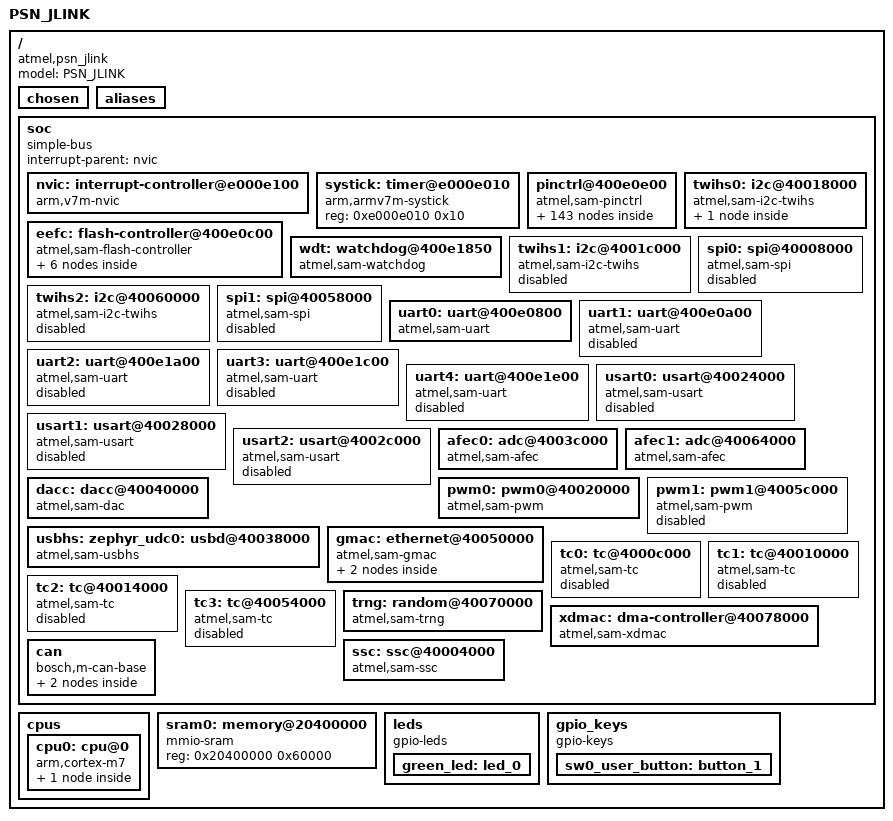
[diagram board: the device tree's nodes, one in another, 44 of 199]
/dts-v1/;

/ {
	#address-cells = < 0x1 >;
	#size-cells = < 0x1 >;
	model = "PSN_JLINK";
	compatible = "atmel,psn_jlink", "atmel,same70q21", "atmel,same70";
	chosen {
		zephyr,flash-controller = &eefc;
		zephyr,entropy = &trng;
		zephyr,console = &uart0;
		zephyr,shell-uart = &uart0;
		zephyr,sram = &sram0;
		zephyr,flash = &flash0;
		zephyr,code-partition = &slot0_partition;
		zephyr,canbus = &can0;
	};
	aliases {
		watchdog0 = &wdt;
		i2c-0 = &twihs0;
		i2c-1 = &twihs1;
		i2c-2 = &twihs2;
		led0 = &green_led;
		sw0 = &sw0_user_button;
	};
	soc {
		#address-cells = < 0x1 >;
		#size-cells = < 0x1 >;
		compatible = "simple-bus";
		interrupt-parent = < &nvic >;
		ranges;
		nvic: interrupt-controller@e000e100 {
			#address-cells = < 0x1 >;
			compatible = "arm,v7m-nvic";
			reg = < 0xe000e100 0xc00 >;
			interrupt-controller;
			#interrupt-cells = < 0x2 >;
			arm,num-irq-priority-bits = < 0x3 >;
			phandle = < 0x1 >;
		};
		systick: timer@e000e010 {
			compatible = "arm,armv7m-systick";
			reg = < 0xe000e010 0x10 >;
		};
		pinctrl@400e0e00 {
			compatible = "atmel,sam-pinctrl";
			#address-cells = < 0x1 >;
			#size-cells = < 0x1 >;
			ranges = < 0x400e0e00 0x400e0e00 0xa00 >;
			pa8b_afec0_adtrg: pa8b_afec0_adtrg {
				atmel,pins = < &pioa 0x8 0x1 >;
				phandle = < 0x19 >;
			};
			pd9c_afec1_adtrg: pd9c_afec1_adtrg {
				atmel,pins = < &piod 0x9 0x2 >;
				phandle = < 0x1a >;
			};
			pd13a_gmac_gcol: pd13a_gmac_gcol {
				atmel,pins = < &piod 0xd 0x0 >;
			};
			pd10a_gmac_gcrs: pd10a_gmac_gcrs {
				atmel,pins = < &piod 0xa 0x0 >;
			};
			pd8a_gmac_gmdc: pd8a_gmac_gmdc {
				atmel,pins = < &piod 0x8 0x0 >;
				phandle = < 0x23 >;
			};
			pd9a_gmac_gmdio: pd9a_gmac_gmdio {
				atmel,pins = < &piod 0x9 0x0 >;
				phandle = < 0x24 >;
			};
			pd14a_gmac_grxck: pd14a_gmac_grxck {
				atmel,pins = < &piod 0xe 0x0 >;
			};
			pd4a_gmac_grxdv: pd4a_gmac_grxdv {
				atmel,pins = < &piod 0x4 0x0 >;
				phandle = < 0x1f >;
			};
			pd7a_gmac_grxer: pd7a_gmac_grxer {
				atmel,pins = < &piod 0x7 0x0 >;
				phandle = < 0x22 >;
			};
			pd5a_gmac_grx0: pd5a_gmac_grx0 {
				atmel,pins = < &piod 0x5 0x0 >;
				phandle = < 0x20 >;
			};
			pd6a_gmac_grx1: pd6a_gmac_grx1 {
				atmel,pins = < &piod 0x6 0x0 >;
				phandle = < 0x21 >;
			};
			pd11a_gmac_grx2: pd11a_gmac_grx2 {
				atmel,pins = < &piod 0xb 0x0 >;
			};
			pd12a_gmac_grx3: pd12a_gmac_grx3 {
				atmel,pins = < &piod 0xc 0x0 >;
			};
			pb1b_gmac_gtsucomp: pb1b_gmac_gtsucomp {
				atmel,pins = < &piob 0x1 0x1 >;
			};
			pb12b_gmac_gtsucomp: pb12b_gmac_gtsucomp {
				atmel,pins = < &piob 0xc 0x1 >;
			};
			pd11c_gmac_gtsucomp: pd11c_gmac_gtsucomp {
				atmel,pins = < &piod 0xb 0x2 >;
			};
			pd20c_gmac_gtsucomp: pd20c_gmac_gtsucomp {
				atmel,pins = < &piod 0x14 0x2 >;
			};
			pd0a_gmac_gtxck: pd0a_gmac_gtxck {
				atmel,pins = < &piod 0x0 0x0 >;
				phandle = < 0x1b >;
			};
			pd1a_gmac_gtxen: pd1a_gmac_gtxen {
				atmel,pins = < &piod 0x1 0x0 >;
				phandle = < 0x1c >;
			};
			pd17a_gmac_gtxer: pd17a_gmac_gtxer {
				atmel,pins = < &piod 0x11 0x0 >;
			};
			pd2a_gmac_gtx0: pd2a_gmac_gtx0 {
				atmel,pins = < &piod 0x2 0x0 >;
				phandle = < 0x1d >;
			};
			pd3a_gmac_gtx1: pd3a_gmac_gtx1 {
				atmel,pins = < &piod 0x3 0x0 >;
				phandle = < 0x1e >;
			};
			pd15a_gmac_gtx2: pd15a_gmac_gtx2 {
				atmel,pins = < &piod 0xf 0x0 >;
			};
			pd16a_gmac_gtx3: pd16a_gmac_gtx3 {
				atmel,pins = < &piod 0x10 0x0 >;
			};
			pd20b_spi0_miso: pd20b_spi0_miso {
				atmel,pins = < &piod 0x14 0x1 >;
			};
			pd21b_spi0_mosi: pd21b_spi0_mosi {
				atmel,pins = < &piod 0x15 0x1 >;
			};
			pb2d_spi0_npcs0: pb2d_spi0_npcs0 {
				atmel,pins = < &piob 0x2 0x3 >;
			};
			pa31a_spi0_npcs1: pa31a_spi0_npcs1 {
				atmel,pins = < &pioa 0x1f 0x0 >;
			};
			pd25b_spi0_npcs1: pd25b_spi0_npcs1 {
				atmel,pins = < &piod 0x19 0x1 >;
			};
			pd12c_spi0_npcs2: pd12c_spi0_npcs2 {
				atmel,pins = < &piod 0xc 0x2 >;
			};
			pd27b_spi0_npcs3: pd27b_spi0_npcs3 {
				atmel,pins = < &piod 0x1b 0x1 >;
				phandle = < 0x10 >;
			};
			pd22b_spi0_spck: pd22b_spi0_spck {
				atmel,pins = < &piod 0x16 0x1 >;
			};
			pc26c_spi1_miso: pc26c_spi1_miso {
				atmel,pins = < &pioc 0x1a 0x2 >;
				phandle = < 0xd >;
			};
			pc27c_spi1_mosi: pc27c_spi1_mosi {
				atmel,pins = < &pioc 0x1b 0x2 >;
				phandle = < 0xe >;
			};
			pc25c_spi1_npcs0: pc25c_spi1_npcs0 {
				atmel,pins = < &pioc 0x19 0x2 >;
			};
			pc28c_spi1_npcs1: pc28c_spi1_npcs1 {
				atmel,pins = < &pioc 0x1c 0x2 >;
			};
			pd0c_spi1_npcs1: pd0c_spi1_npcs1 {
				atmel,pins = < &piod 0x0 0x2 >;
			};
			pc29c_spi1_npcs2: pc29c_spi1_npcs2 {
				atmel,pins = < &pioc 0x1d 0x2 >;
			};
			pd1c_spi1_npcs2: pd1c_spi1_npcs2 {
				atmel,pins = < &piod 0x1 0x2 >;
			};
			pc30c_spi1_npcs3: pc30c_spi1_npcs3 {
				atmel,pins = < &pioc 0x1e 0x2 >;
			};
			pd2c_spi1_npcs3: pd2c_spi1_npcs3 {
				atmel,pins = < &piod 0x2 0x2 >;
			};
			pc24c_spi1_spck: pc24c_spi1_spck {
				atmel,pins = < &pioc 0x18 0x2 >;
				phandle = < 0xf >;
			};
			pa10c_ssc_rd: pa10c_ssc_rd {
				atmel,pins = < &pioa 0xa 0x2 >;
				phandle = < 0x29 >;
			};
			pd24b_ssc_rf: pd24b_ssc_rf {
				atmel,pins = < &piod 0x18 0x1 >;
				phandle = < 0x27 >;
			};
			pa22a_ssc_rk: pa22a_ssc_rk {
				atmel,pins = < &pioa 0x16 0x0 >;
				phandle = < 0x28 >;
			};
			pb5d_ssc_td: pb5d_ssc_td {
				atmel,pins = < &piob 0x5 0x3 >;
				phandle = < 0x2c >;
			};
			pd10c_ssc_td: pd10c_ssc_td {
				atmel,pins = < &piod 0xa 0x2 >;
			};
			pd26b_ssc_td: pd26b_ssc_td {
				atmel,pins = < &piod 0x1a 0x1 >;
			};
			pb0d_ssc_tf: pb0d_ssc_tf {
				atmel,pins = < &piob 0x0 0x3 >;
				phandle = < 0x2a >;
			};
			pb1d_ssc_tk: pb1d_ssc_tk {
				atmel,pins = < &piob 0x1 0x3 >;
				phandle = < 0x2b >;
			};
			pa4a_twihs0_twck0: pa4a_twihs0_twck0 {
				atmel,pins = < &pioa 0x4 0x0 >;
				phandle = < 0x7 >;
			};
			pa3a_twihs0_twd0: pa3a_twihs0_twd0 {
				atmel,pins = < &pioa 0x3 0x0 >;
				phandle = < 0x8 >;
			};
			pb5a_twihs1_twck1: pb5a_twihs1_twck1 {
				atmel,pins = < &piob 0x5 0x0 >;
				phandle = < 0x9 >;
			};
			pb4a_twihs1_twd1: pb4a_twihs1_twd1 {
				atmel,pins = < &piob 0x4 0x0 >;
				phandle = < 0xa >;
			};
			pd28c_twihs2_twck2: pd28c_twihs2_twck2 {
				atmel,pins = < &piod 0x1c 0x2 >;
				phandle = < 0xb >;
			};
			pd27c_twihs2_twd2: pd27c_twihs2_twd2 {
				atmel,pins = < &piod 0x1b 0x2 >;
				phandle = < 0xc >;
			};
			pa9a_uart0_urxd0: pa9a_uart0_urxd0 {
				atmel,pins = < &pioa 0x9 0x0 >;
				phandle = < 0x11 >;
			};
			pa10a_uart0_utxd0: pa10a_uart0_utxd0 {
				atmel,pins = < &pioa 0xa 0x0 >;
				phandle = < 0x12 >;
			};
			pa5c_uart1_urxd1: pa5c_uart1_urxd1 {
				atmel,pins = < &pioa 0x5 0x2 >;
			};
			pa4c_uart1_utxd1: pa4c_uart1_utxd1 {
				atmel,pins = < &pioa 0x4 0x2 >;
			};
			pa6c_uart1_utxd1: pa6c_uart1_utxd1 {
				atmel,pins = < &pioa 0x6 0x2 >;
			};
			pd26d_uart1_utxd1: pd26d_uart1_utxd1 {
				atmel,pins = < &piod 0x1a 0x3 >;
			};
			pd25c_uart2_urxd2: pd25c_uart2_urxd2 {
				atmel,pins = < &piod 0x19 0x2 >;
			};
			pd26c_uart2_utxd2: pd26c_uart2_utxd2 {
				atmel,pins = < &piod 0x1a 0x2 >;
			};
			pd28a_uart3_urxd3: pd28a_uart3_urxd3 {
				atmel,pins = < &piod 0x1c 0x0 >;
			};
			pd30a_uart3_utxd3: pd30a_uart3_utxd3 {
				atmel,pins = < &piod 0x1e 0x0 >;
			};
			pd31b_uart3_utxd3: pd31b_uart3_utxd3 {
				atmel,pins = < &piod 0x1f 0x1 >;
			};
			pd18c_uart4_urxd4: pd18c_uart4_urxd4 {
				atmel,pins = < &piod 0x12 0x2 >;
			};
			pd3c_uart4_utxd4: pd3c_uart4_utxd4 {
				atmel,pins = < &piod 0x3 0x2 >;
			};
			pd19c_uart4_utxd4: pd19c_uart4_utxd4 {
				atmel,pins = < &piod 0x13 0x2 >;
			};
			pb2c_usart0_cts0: pb2c_usart0_cts0 {
				atmel,pins = < &piob 0x2 0x2 >;
			};
			pd0d_usart0_dcd0: pd0d_usart0_dcd0 {
				atmel,pins = < &piod 0x0 0x3 >;
			};
			pd2d_usart0_dsr0: pd2d_usart0_dsr0 {
				atmel,pins = < &piod 0x2 0x3 >;
			};
			pd1d_usart0_dtr0: pd1d_usart0_dtr0 {
				atmel,pins = < &piod 0x1 0x3 >;
			};
			pd3d_usart0_ri0: pd3d_usart0_ri0 {
				atmel,pins = < &piod 0x3 0x3 >;
			};
			pb3c_usart0_rts0: pb3c_usart0_rts0 {
				atmel,pins = < &piob 0x3 0x2 >;
			};
			pb0c_usart0_rxd0: pb0c_usart0_rxd0 {
				atmel,pins = < &piob 0x0 0x2 >;
				phandle = < 0x13 >;
			};
			pb13c_usart0_sck0: pb13c_usart0_sck0 {
				atmel,pins = < &piob 0xd 0x2 >;
			};
			pb1c_usart0_txd0: pb1c_usart0_txd0 {
				atmel,pins = < &piob 0x1 0x2 >;
				phandle = < 0x14 >;
			};
			pa25a_usart1_cts1: pa25a_usart1_cts1 {
				atmel,pins = < &pioa 0x19 0x0 >;
			};
			pa26a_usart1_dcd1: pa26a_usart1_dcd1 {
				atmel,pins = < &pioa 0x1a 0x0 >;
			};
			pa28a_usart1_dsr1: pa28a_usart1_dsr1 {
				atmel,pins = < &pioa 0x1c 0x0 >;
			};
			pa27a_usart1_dtr1: pa27a_usart1_dtr1 {
				atmel,pins = < &pioa 0x1b 0x0 >;
			};
			pa3b_usart1_loncol1: pa3b_usart1_loncol1 {
				atmel,pins = < &pioa 0x3 0x1 >;
			};
			pa29a_usart1_ri1: pa29a_usart1_ri1 {
				atmel,pins = < &pioa 0x1d 0x0 >;
			};
			pa24a_usart1_rts1: pa24a_usart1_rts1 {
				atmel,pins = < &pioa 0x18 0x0 >;
			};
			pa21a_usart1_rxd1: pa21a_usart1_rxd1 {
				atmel,pins = < &pioa 0x15 0x0 >;
				phandle = < 0x15 >;
			};
			pa23a_usart1_sck1: pa23a_usart1_sck1 {
				atmel,pins = < &pioa 0x17 0x0 >;
			};
			pb4d_usart1_txd1: pb4d_usart1_txd1 {
				atmel,pins = < &piob 0x4 0x3 >;
				phandle = < 0x16 >;
			};
			pd19b_usart2_cts2: pd19b_usart2_cts2 {
				atmel,pins = < &piod 0x13 0x1 >;
			};
			pd4d_usart2_dcd2: pd4d_usart2_dcd2 {
				atmel,pins = < &piod 0x4 0x3 >;
			};
			pd6d_usart2_dsr2: pd6d_usart2_dsr2 {
				atmel,pins = < &piod 0x6 0x3 >;
			};
			pd5d_usart2_dtr2: pd5d_usart2_dtr2 {
				atmel,pins = < &piod 0x5 0x3 >;
			};
			pd7d_usart2_ri2: pd7d_usart2_ri2 {
				atmel,pins = < &piod 0x7 0x3 >;
			};
			pd18b_usart2_rts2: pd18b_usart2_rts2 {
				atmel,pins = < &piod 0x12 0x1 >;
			};
			pd15b_usart2_rxd2: pd15b_usart2_rxd2 {
				atmel,pins = < &piod 0xf 0x1 >;
				phandle = < 0x17 >;
			};
			pd17b_usart2_sck2: pd17b_usart2_sck2 {
				atmel,pins = < &piod 0x11 0x1 >;
			};
			pd16b_usart2_txd2: pd16b_usart2_txd2 {
				atmel,pins = < &piod 0x10 0x1 >;
				phandle = < 0x18 >;
			};
			pa4b_tc0_tclk0: pa4b_tc0_tclk0 {
				atmel,pins = < &pioa 0x4 0x1 >;
			};
			pa28b_tc0_tclk1: pa28b_tc0_tclk1 {
				atmel,pins = < &pioa 0x1c 0x1 >;
			};
			pa29b_tc0_tclk2: pa29b_tc0_tclk2 {
				atmel,pins = < &pioa 0x1d 0x1 >;
			};
			pa0b_tc0_tioa0: pa0b_tc0_tioa0 {
				atmel,pins = < &pioa 0x0 0x1 >;
			};
			pa15b_tc0_tioa1: pa15b_tc0_tioa1 {
				atmel,pins = < &pioa 0xf 0x1 >;
			};
			pa26b_tc0_tioa2: pa26b_tc0_tioa2 {
				atmel,pins = < &pioa 0x1a 0x1 >;
			};
			pa1b_tc0_tiob0: pa1b_tc0_tiob0 {
				atmel,pins = < &pioa 0x1 0x1 >;
			};
			pa16b_tc0_tiob1: pa16b_tc0_tiob1 {
				atmel,pins = < &pioa 0x10 0x1 >;
			};
			pa27b_tc0_tiob2: pa27b_tc0_tiob2 {
				atmel,pins = < &pioa 0x1b 0x1 >;
			};
			pc25b_tc1_tclk3: pc25b_tc1_tclk3 {
				atmel,pins = < &pioc 0x19 0x1 >;
			};
			pc28b_tc1_tclk4: pc28b_tc1_tclk4 {
				atmel,pins = < &pioc 0x1c 0x1 >;
			};
			pc31b_tc1_tclk5: pc31b_tc1_tclk5 {
				atmel,pins = < &pioc 0x1f 0x1 >;
			};
			pc23b_tc1_tioa3: pc23b_tc1_tioa3 {
				atmel,pins = < &pioc 0x17 0x1 >;
			};
			pc26b_tc1_tioa4: pc26b_tc1_tioa4 {
				atmel,pins = < &pioc 0x1a 0x1 >;
			};
			pc29b_tc1_tioa5: pc29b_tc1_tioa5 {
				atmel,pins = < &pioc 0x1d 0x1 >;
			};
			pc24b_tc1_tiob3: pc24b_tc1_tiob3 {
				atmel,pins = < &pioc 0x18 0x1 >;
			};
			pc27b_tc1_tiob4: pc27b_tc1_tiob4 {
				atmel,pins = < &pioc 0x1b 0x1 >;
			};
			pc30b_tc1_tiob5: pc30b_tc1_tiob5 {
				atmel,pins = < &pioc 0x1e 0x1 >;
			};
			pc7b_tc2_tclk6: pc7b_tc2_tclk6 {
				atmel,pins = < &pioc 0x7 0x1 >;
			};
			pc10b_tc2_tclk7: pc10b_tc2_tclk7 {
				atmel,pins = < &pioc 0xa 0x1 >;
			};
			pc14b_tc2_tclk8: pc14b_tc2_tclk8 {
				atmel,pins = < &pioc 0xe 0x1 >;
			};
			pc5b_tc2_tioa6: pc5b_tc2_tioa6 {
				atmel,pins = < &pioc 0x5 0x1 >;
			};
			pc8b_tc2_tioa7: pc8b_tc2_tioa7 {
				atmel,pins = < &pioc 0x8 0x1 >;
			};
			pc11b_tc2_tioa8: pc11b_tc2_tioa8 {
				atmel,pins = < &pioc 0xb 0x1 >;
			};
			pc6b_tc2_tiob6: pc6b_tc2_tiob6 {
				atmel,pins = < &pioc 0x6 0x1 >;
			};
			pc9b_tc2_tiob7: pc9b_tc2_tiob7 {
				atmel,pins = < &pioc 0x9 0x1 >;
			};
			pc12b_tc2_tiob8: pc12b_tc2_tiob8 {
				atmel,pins = < &pioc 0xc 0x1 >;
			};
			pe2b_tc3_tclk9: pe2b_tc3_tclk9 {
				atmel,pins = < &pioe 0x2 0x1 >;
			};
			pe5b_tc3_tclk10: pe5b_tc3_tclk10 {
				atmel,pins = < &pioe 0x5 0x1 >;
			};
			pd24c_tc3_tclk11: pd24c_tc3_tclk11 {
				atmel,pins = < &piod 0x18 0x2 >;
			};
			pe0b_tc3_tioa9: pe0b_tc3_tioa9 {
				atmel,pins = < &pioe 0x0 0x1 >;
			};
			pe3b_tc3_tioa10: pe3b_tc3_tioa10 {
				atmel,pins = < &pioe 0x3 0x1 >;
			};
			pd21c_tc3_tioa11: pd21c_tc3_tioa11 {
				atmel,pins = < &piod 0x15 0x2 >;
			};
			pe1b_tc3_tiob9: pe1b_tc3_tiob9 {
				atmel,pins = < &pioe 0x1 0x1 >;
			};
			pe4b_tc3_tiob10: pe4b_tc3_tiob10 {
				atmel,pins = < &pioe 0x4 0x1 >;
			};
			pd22c_tc3_tiob11: pd22c_tc3_tiob11 {
				atmel,pins = < &piod 0x16 0x2 >;
			};
			pb3a_can0_rx0: pb3a_can0_rx0 {
				atmel,pins = < &piob 0x3 0x0 >;
				phandle = < 0x2d >;
			};
			pb2a_can0_tx0: pb2a_can0_tx0 {
				atmel,pins = < &piob 0x2 0x0 >;
				phandle = < 0x2e >;
			};
			pc12c_can1_rx1: pc12c_can1_rx1 {
				atmel,pins = < &pioc 0xc 0x2 >;
			};
			pc14c_can1_tx1: pc14c_can1_tx1 {
				atmel,pins = < &pioc 0xe 0x2 >;
			};
			pioa: gpio@400e0e00 {
				compatible = "atmel,sam-gpio";
				reg = < 0x400e0e00 0x190 >;
				interrupts = < 0xa 0x1 >;
				peripheral-id = < 0xa >;
				label = "PORTA";
				gpio-controller;
				#gpio-cells = < 0x2 >;
				#atmel,pin-cells = < 0x2 >;
				phandle = < 0x2 >;
			};
			piob: gpio@400e1000 {
				compatible = "atmel,sam-gpio";
				reg = < 0x400e1000 0x190 >;
				interrupts = < 0xb 0x1 >;
				peripheral-id = < 0xb >;
				label = "PORTB";
				gpio-controller;
				#gpio-cells = < 0x2 >;
				#atmel,pin-cells = < 0x2 >;
				phandle = < 0x4 >;
			};
			pioc: gpio@400e1200 {
				compatible = "atmel,sam-gpio";
				reg = < 0x400e1200 0x190 >;
				interrupts = < 0xc 0x1 >;
				peripheral-id = < 0xc >;
				label = "PORTC";
				gpio-controller;
				#gpio-cells = < 0x2 >;
				#atmel,pin-cells = < 0x2 >;
				phandle = < 0x5 >;
			};
			piod: gpio@400e1400 {
				compatible = "atmel,sam-gpio";
				reg = < 0x400e1400 0x190 >;
				interrupts = < 0x10 0x1 >;
				peripheral-id = < 0x10 >;
				label = "PORTD";
				gpio-controller;
				#gpio-cells = < 0x2 >;
				#atmel,pin-cells = < 0x2 >;
				phandle = < 0x3 >;
			};
			pioe: gpio@400e1600 {
				compatible = "atmel,sam-gpio";
				reg = < 0x400e1600 0x190 >;
				interrupts = < 0x11 0x1 >;
				peripheral-id = < 0x11 >;
				label = "PORTE";
				gpio-controller;
				#gpio-cells = < 0x2 >;
				#atmel,pin-cells = < 0x2 >;
				phandle = < 0x6 >;
			};
		};
		eefc: flash-controller@400e0c00 {
			compatible = "atmel,sam-flash-controller";
			label = "FLASH_CTRL";
			reg = < 0x400e0c00 0x200 >;
			interrupts = < 0x6 0x0 >;
			peripheral-id = < 0x6 >;
			#address-cells = < 0x1 >;
			#size-cells = < 0x1 >;
			flash0: flash@400000 {
				compatible = "soc-nv-flash";
				label = "FLASH_E70";
				write-block-size = < 0x10 >;
				erase-block-size = < 0x2000 >;
				reg = < 0x400000 0x200000 >;
				partitions {
					compatible = "fixed-partitions";
					#address-cells = < 0x1 >;
					#size-cells = < 0x1 >;
					boot_partition: partition@0 {
						label = "mcuboot";
						reg = < 0x0 0x10000 >;
						read-only;
					};
					slot0_partition: partition@20000 {
						label = "image-0";
						reg = < 0x20000 0xe0000 >;
					};
					slot1_partition: partition@100000 {
						label = "image-1";
						reg = < 0x100000 0xe0000 >;
					};
					scratch_partition: partition@1e0000 {
						label = "image-scratch";
						reg = < 0x1e0000 0x20000 >;
					};
				};
			};
		};
		wdt: watchdog@400e1850 {
			compatible = "atmel,sam-watchdog";
			reg = < 0x400e1850 0xc >;
			interrupts = < 0x4 0x0 >;
			peripheral-id = < 0x4 >;
			label = "WATCHDOG_0";
			status = "okay";
		};
		twihs0: i2c@40018000 {
			compatible = "atmel,sam-i2c-twihs";
			clock-frequency = < 0x186a0 >;
			#address-cells = < 0x1 >;
			#size-cells = < 0x0 >;
			reg = < 0x40018000 0x12b >;
			interrupts = < 0x13 0x0 >;
			peripheral-id = < 0x13 >;
			label = "I2C_0";
			status = "okay";
			pinctrl-0 = < &pa4a_twihs0_twck0 &pa3a_twihs0_twd0 >;
			ag416@38 {
				compatible = "fujikaru,ag416";
				reg = < 0x38 >;
				label = "AG416";
			};
		};
		twihs1: i2c@4001c000 {
			compatible = "atmel,sam-i2c-twihs";
			clock-frequency = < 0x186a0 >;
			#address-cells = < 0x1 >;
			#size-cells = < 0x0 >;
			reg = < 0x4001c000 0x12b >;
			interrupts = < 0x14 0x0 >;
			peripheral-id = < 0x14 >;
			label = "I2C_1";
			status = "disabled";
			pinctrl-0 = < &pb5a_twihs1_twck1 &pb4a_twihs1_twd1 >;
		};
		twihs2: i2c@40060000 {
			compatible = "atmel,sam-i2c-twihs";
			clock-frequency = < 0x186a0 >;
			#address-cells = < 0x1 >;
			#size-cells = < 0x0 >;
			reg = < 0x40060000 0x12b >;
			interrupts = < 0x29 0x0 >;
			peripheral-id = < 0x29 >;
			label = "I2C_2";
			status = "disabled";
			pinctrl-0 = < &pd28c_twihs2_twck2 &pd27c_twihs2_twd2 >;
		};
		spi0: spi@40008000 {
			compatible = "atmel,sam-spi";
			#address-cells = < 0x1 >;
			#size-cells = < 0x0 >;
			reg = < 0x40008000 0x4000 >;
			interrupts = < 0x15 0x0 >;
			peripheral-id = < 0x15 >;
			label = "SPI_0";
			status = "disabled";
			pinctrl-0 = < &pc26c_spi1_miso &pc27c_spi1_mosi &pc24c_spi1_spck &pd27b_spi0_npcs3 >;
		};
		spi1: spi@40058000 {
			compatible = "atmel,sam-spi";
			#address-cells = < 0x1 >;
			#size-cells = < 0x0 >;
			reg = < 0x40058000 0x4000 >;
			interrupts = < 0x2a 0x0 >;
			peripheral-id = < 0x2a >;
			label = "SPI_1";
			status = "disabled";
			pinctrl-0 = < &pc26c_spi1_miso &pc27c_spi1_mosi &pc24c_spi1_spck >;
		};
		uart0: uart@400e0800 {
			compatible = "atmel,sam-uart";
			reg = < 0x400e0800 0x100 >;
			interrupts = < 0x7 0x1 >;
			peripheral-id = < 0x7 >;
			status = "okay";
			label = "UART_0";
			pinctrl-0 = < &pa9a_uart0_urxd0 &pa10a_uart0_utxd0 >;
			current-speed = < 0x1c200 >;
		};
		uart1: uart@400e0a00 {
			compatible = "atmel,sam-uart";
			reg = < 0x400e0a00 0x100 >;
			interrupts = < 0x8 0x1 >;
			peripheral-id = < 0x8 >;
			status = "disabled";
			label = "UART_1";
		};
		uart2: uart@400e1a00 {
			compatible = "atmel,sam-uart";
			reg = < 0x400e1a00 0x100 >;
			interrupts = < 0x2c 0x1 >;
			peripheral-id = < 0x2c >;
			status = "disabled";
			label = "UART_2";
		};
		uart3: uart@400e1c00 {
			compatible = "atmel,sam-uart";
			reg = < 0x400e1c00 0x100 >;
			interrupts = < 0x2d 0x1 >;
			peripheral-id = < 0x2d >;
			status = "disabled";
			label = "UART_3";
		};
		uart4: uart@400e1e00 {
			compatible = "atmel,sam-uart";
			reg = < 0x400e1e00 0x100 >;
			interrupts = < 0x2e 0x1 >;
			peripheral-id = < 0x2e >;
			status = "disabled";
			label = "UART_4";
		};
		usart0: usart@40024000 {
			compatible = "atmel,sam-usart";
			reg = < 0x40024000 0x100 >;
			interrupts = < 0xd 0x0 >;
			peripheral-id = < 0xd >;
			status = "disabled";
			label = "USART_0";
			pinctrl-0 = < &pb0c_usart0_rxd0 &pb1c_usart0_txd0 >;
		};
		usart1: usart@40028000 {
			compatible = "atmel,sam-usart";
			reg = < 0x40028000 0x100 >;
			interrupts = < 0xe 0x0 >;
			peripheral-id = < 0xe >;
			status = "disabled";
			label = "USART_1";
			pinctrl-0 = < &pa21a_usart1_rxd1 &pb4d_usart1_txd1 >;
		};
		usart2: usart@4002c000 {
			compatible = "atmel,sam-usart";
			reg = < 0x4002c000 0x100 >;
			interrupts = < 0xf 0x0 >;
			peripheral-id = < 0xf >;
			status = "disabled";
			label = "USART_2";
			pinctrl-0 = < &pd15b_usart2_rxd2 &pd16b_usart2_txd2 >;
		};
		afec0: adc@4003c000 {
			compatible = "atmel,sam-afec";
			reg = < 0x4003c000 0x100 >;
			interrupts = < 0x1d 0x0 >;
			peripheral-id = < 0x1d >;
			status = "okay";
			label = "ADC_0";
			#io-channel-cells = < 0x1 >;
			pinctrl-0 = < &pa8b_afec0_adtrg >;
		};
		afec1: adc@40064000 {
			compatible = "atmel,sam-afec";
			reg = < 0x40064000 0x100 >;
			interrupts = < 0x28 0x0 >;
			peripheral-id = < 0x28 >;
			status = "okay";
			label = "ADC_1";
			#io-channel-cells = < 0x1 >;
			pinctrl-0 = < &pd9c_afec1_adtrg >;
		};
		dacc: dacc@40040000 {
			compatible = "atmel,sam-dac";
			reg = < 0x40040000 0x100 >;
			interrupts = < 0x1e 0x0 >;
			peripheral-id = < 0x1e >;
			status = "okay";
			label = "DACC";
			#io-channel-cells = < 0x1 >;
		};
		pwm0: pwm0@40020000 {
			compatible = "atmel,sam-pwm";
			reg = < 0x40020000 0x4000 >;
			interrupts = < 0x1f 0x0 >;
			peripheral-id = < 0x1f >;
			status = "okay";
			label = "PWM_0";
			prescaler = < 0xa >;
			divider = < 0x1 >;
			#pwm-cells = < 0x2 >;
		};
		pwm1: pwm1@4005c000 {
			compatible = "atmel,sam-pwm";
			reg = < 0x4005c000 0x4000 >;
			interrupts = < 0x3c 0x0 >;
			peripheral-id = < 0x3c >;
			status = "disabled";
			label = "PWM_1";
			prescaler = < 0xa >;
			divider = < 0x1 >;
			#pwm-cells = < 0x2 >;
		};
		usbhs: zephyr_udc0: usbd@40038000 {
			compatible = "atmel,sam-usbhs";
			#address-cells = < 0x1 >;
			#size-cells = < 0x0 >;
			reg = < 0x40038000 0x4000 >;
			interrupts = < 0x22 0x0 >;
			interrupt-names = "usbhs";
			maximum-speed = "high-speed";
			num-bidir-endpoints = < 0xa >;
			peripheral-id = < 0x22 >;
			status = "okay";
			label = "USBHS";
		};
		gmac: ethernet@40050000 {
			compatible = "atmel,sam-gmac";
			reg = < 0x40050000 0x4000 >;
			peripheral-id = < 0x27 >;
			interrupts = < 0x27 0x0 >, < 0x42 0x0 >, < 0x43 0x0 >;
			interrupt-names = "gmac", "q1", "q2";
			num-queues = < 0x3 >;
			local-mac-address = [ 00 00 00 00 00 00 ];
			label = "GMAC";
			status = "okay";
			pinctrl-0 = < &pd0a_gmac_gtxck &pd1a_gmac_gtxen &pd2a_gmac_gtx0 &pd3a_gmac_gtx1 &pd4a_gmac_grxdv &pd5a_gmac_grx0 &pd6a_gmac_grx1 &pd7a_gmac_grxer >;
			mdio: mdio {
				compatible = "atmel,sam-mdio";
				label = "MDIO";
				status = "okay";
				pinctrl-0 = < &pd8a_gmac_gmdc &pd9a_gmac_gmdio >;
				phandle = < 0x25 >;
			};
			phy: phy {
				compatible = "ethernet-phy";
				status = "okay";
				address = < 0x0 >;
				mdio = < &mdio >;
			};
		};
		tc0: tc@4000c000 {
			compatible = "atmel,sam-tc";
			reg = < 0x4000c000 0x100 >;
			interrupts = < 0x17 0x0 0x18 0x0 0x19 0x0 >;
			peripheral-id = < 0x17 0x18 0x19 >;
			status = "disabled";
			label = "TC0";
			pinctrl-0;
		};
		tc1: tc@40010000 {
			compatible = "atmel,sam-tc";
			reg = < 0x40010000 0x100 >;
			interrupts = < 0x1a 0x0 0x1b 0x0 0x1c 0x0 >;
			peripheral-id = < 0x1a 0x1b 0x1c >;
			status = "disabled";
			label = "TC1";
			pinctrl-0;
		};
		tc2: tc@40014000 {
			compatible = "atmel,sam-tc";
			reg = < 0x40014000 0x100 >;
			interrupts = < 0x2f 0x0 0x30 0x0 0x31 0x0 >;
			peripheral-id = < 0x2f 0x30 0x31 >;
			status = "disabled";
			label = "TC2";
			pinctrl-0;
		};
		tc3: tc@40054000 {
			compatible = "atmel,sam-tc";
			reg = < 0x40054000 0x100 >;
			interrupts = < 0x32 0x0 0x33 0x0 0x34 0x0 >;
			peripheral-id = < 0x32 0x33 0x34 >;
			status = "disabled";
			label = "TC3";
			pinctrl-0;
		};
		trng: random@40070000 {
			compatible = "atmel,sam-trng";
			reg = < 0x40070000 0x4000 >;
			interrupts = < 0x39 0x0 >;
			peripheral-id = < 0x39 >;
			status = "okay";
			label = "TRNG";
		};
		xdmac: dma-controller@40078000 {
			compatible = "atmel,sam-xdmac";
			reg = < 0x40078000 0x400 >;
			interrupts = < 0x3a 0x0 >;
			peripheral-id = < 0x3a >;
			label = "DMA_0";
			#dma-cells = < 0x2 >;
			phandle = < 0x26 >;
		};
		ssc: ssc@40004000 {
			compatible = "atmel,sam-ssc";
			reg = < 0x40004000 0x400 >;
			interrupts = < 0x16 0x0 >;
			peripheral-id = < 0x16 >;
			label = "I2S_0";
			status = "okay";
			dma-names = "rx", "tx";
			dmas = < &xdmac 0x16 0x21 >, < &xdmac 0x17 0x20 >;
			pinctrl-0 = < &pd24b_ssc_rf &pa22a_ssc_rk &pa10c_ssc_rd &pb0d_ssc_tf &pb1d_ssc_tk &pb5d_ssc_td >;
		};
		can {
			compatible = "bosch,m-can-base";
			#address-cells = < 0x1 >;
			#size-cells = < 0x1 >;
			std-filter-elements = < 0x1c >;
			ext-filter-elements = < 0x8 >;
			rx-fifo0-elements = < 0x3 >;
			rx-fifo1-elements = < 0x3 >;
			rx-buffer-elements = < 0x0 >;
			tx-buffer-elements = < 0x1 >;
			can0: can@40030000 {
				compatible = "atmel,sam-can";
				#address-cells = < 0x1 >;
				#size-cells = < 0x0 >;
				reg = < 0x40030000 0x100 >;
				reg-names = "m_can";
				interrupts = < 0x23 0x0 >, < 0x24 0x0 >;
				interrupt-names = "LINE_0", "LINE_1";
				peripheral-id = < 0x23 >;
				status = "okay";
				label = "CAN_0";
				pinctrl-0 = < &pb3a_can0_rx0 &pb2a_can0_tx0 >;
				bus-speed = < 0x1e848 >;
				sjw = < 0x1 >;
				sample-point = < 0x36b >;
				bus-speed-data = < 0xf4240 >;
				sjw-data = < 0x1 >;
				sample-point-data = < 0x36b >;
			};
			can1: can@40034000 {
				compatible = "atmel,sam-can";
				#address-cells = < 0x1 >;
				#size-cells = < 0x0 >;
				reg = < 0x40034000 0x100 >;
				reg-names = "m_can";
				interrupts = < 0x25 0x0 >, < 0x26 0x0 >;
				interrupt-names = "LINE_0", "LINE_1";
				peripheral-id = < 0x25 >;
				status = "disabled";
				label = "CAN_1";
			};
		};
	};
	cpus {
		#address-cells = < 0x1 >;
		#size-cells = < 0x0 >;
		cpu0: cpu@0 {
			device_type = "cpu";
			compatible = "arm,cortex-m7";
			reg = < 0x0 >;
			#address-cells = < 0x1 >;
			#size-cells = < 0x1 >;
			clock-frequency = < 0x11e1a300 >;
			mpu: mpu@e000ed90 {
				compatible = "arm,armv7m-mpu";
				reg = < 0xe000ed90 0x40 >;
				arm,num-mpu-regions = < 0x10 >;
			};
		};
	};
	sram0: memory@20400000 {
		compatible = "mmio-sram";
		reg = < 0x20400000 0x60000 >;
	};
	leds {
		compatible = "gpio-leds";
		green_led: led_0 {
			gpios = < &pioa 0xb 0x1 >;
			label = "User LED";
		};
	};
	gpio_keys {
		compatible = "gpio-keys";
		sw0_user_button: button_1 {
			label = "User Button";
			gpios = < &pioa 0xc 0x11 >;
		};
	};
};
